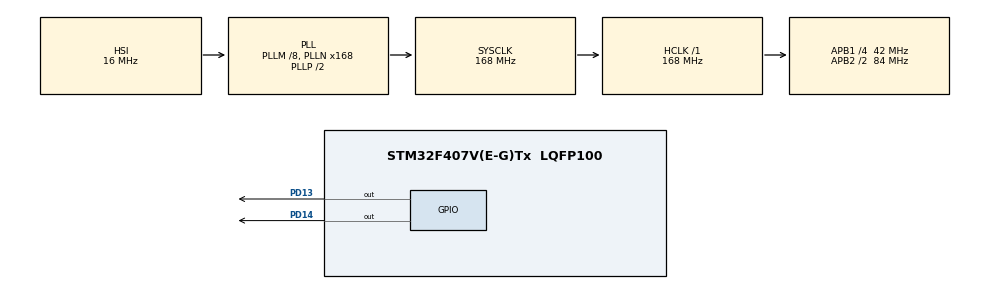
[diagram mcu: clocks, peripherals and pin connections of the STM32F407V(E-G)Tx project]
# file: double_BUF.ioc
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Mcu.Family=STM32F4
Dma.ADC1.0.Instance=DMA2_Stream0
RCC.CortexFreq_Value=168000000
ADC1.Rank-0\#ChannelRegularConversion=1
VP_ADC1_TempSens_Input.Mode=IN-TempSens
ADC1.ContinuousConvMode=ENABLE
RCC.APB1CLKDivider=RCC_HCLK_DIV4
RCC.SYSCLKSource=RCC_SYSCLKSOURCE_PLLCLK
ProjectManager.StackSize=0x400
PD13.Signal=GPIO_Output
Dma.ADC1.0.PeriphDataAlignment=DMA_PDATAALIGN_HALFWORD
ProjectManager.TargetToolchain=STM32CubeIDE
Dma.ADC1.0.Mode=DMA_CIRCULAR
RCC.HCLKFreq_Value=168000000
ADC1.Resolution=ADC_RESOLUTION_8B
Dma.ADC1.0.Priority=DMA_PRIORITY_HIGH
RCC.APB2TimFreq_Value=168000000
Dma.ADC1.0.Direction=DMA_PERIPH_TO_MEMORY
NVIC.DMA2_Stream0_IRQn=true\:0\:0\:false\:false\:true\:false\:true
Dma.ADC1.0.MemDataAlignment=DMA_MDATAALIGN_HALFWORD
RCC.AHBFreq_Value=168000000
ADC1.Channel-0\#ChannelRegularConversion=ADC_CHANNEL_TEMPSENSOR
RCC.HSE_VALUE=8000000
board=STM32F407G-DISC1
RCC.VCOOutputFreq_Value=336000000
RCC.APB2Freq_Value=84000000
Dma.ADC1.0.PeriphInc=DMA_PINC_DISABLE
ADC1.DMAContinuousRequests=ENABLE
ADC1.NbrOfConversion=1
Mcu.Name=STM32F407V(E-G)Tx
ADC1.SamplingTime-0\#ChannelRegularConversion=ADC_SAMPLETIME_28CYCLES
PD14.Signal=GPIO_Output
RCC.48MHZClocksFreq_Value=48000000
RCC.SYSCLKFreq_VALUE=168000000
Mcu.Package=LQFP100
ADC1.master=1
Dma.ADC1.0.MemInc=DMA_MINC_ENABLE
ProjectManager.HeapSize=0x200
RCC.HSI_VALUE=16000000
RCC.PLLQ=7
NVIC.PriorityGroup=NVIC_PRIORITYGROUP_0
ADC1.NbrOfConversionFlag=1
RCC.APB2CLKDivider=RCC_HCLK_DIV2
RCC.PLLM=8
RCC.PLLN=168
RCC.APB1TimFreq_Value=84000000
Dma.ADC1.0.FIFOMode=DMA_FIFOMODE_DISABLE
Dma.Request0=ADC1
RCC.APB1Freq_Value=42000000

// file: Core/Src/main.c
/* USER CODE BEGIN Header */
/**
  ******************************************************************************
  * @file           : main.c
  * @brief          : Main program body
  ******************************************************************************
  * @attention
  *
  * <h2><center>&copy; Copyright (c) 2021 STMicroelectronics.
  * All rights reserved.</center></h2>
  *
  * This software component is licensed by ST under Ultimate Liberty license
  * SLA0044, the "License"; You may not use this file except in compliance with
  * the License. You may obtain a copy of the License at:
  *                             www.st.com/SLA0044
  *
  ******************************************************************************
  */
/* USER CODE END Header */
#include "main.h"

ADC_HandleTypeDef hadc1;
DMA_HandleTypeDef hdma_adc1;

/* USER CODE BEGIN PV */
//double buffering variables
int buflen=240;
uint16_t bufDMA[480];
uint16_t buf1[240];
uint16_t buf2[240];

uint8_t DMA_status=0; //0==empty 1==half 2==full

/* USER CODE END PV */

void SystemClock_Config(void);
static void MX_GPIO_Init(void);
static void MX_DMA_Init(void);
static void MX_ADC1_Init(void);

int main(void)
{

  /* MCU Configuration--------------------------------------------------------*/

  /* Reset of all peripherals, Initializes the Flash interface and the Systick. */
  HAL_Init();

  /* Configure the system clock */
  SystemClock_Config();

  /* Initialize all configured peripherals */
  MX_GPIO_Init();
  MX_DMA_Init();
  MX_ADC1_Init();
  /* USER CODE BEGIN 2 */
  HAL_ADC_Start_DMA(&hadc1, &bufDMA, 2*buflen);

  /* USER CODE END 2 */

  /* Infinite loop */
  while (1)
  {

    /* USER CODE BEGIN 3 */

      // Start ADC Conversion
      // Pass (The ADC Instance, Result Buffer Address, Buffer Length)

  }
  /* USER CODE END 3 */
}

void SystemClock_Config(void)
{
  RCC_OscInitTypeDef RCC_OscInitStruct = {0};
  RCC_ClkInitTypeDef RCC_ClkInitStruct = {0};

  /** Configure the main internal regulator output voltage
  */
  __HAL_RCC_PWR_CLK_ENABLE();
  __HAL_PWR_VOLTAGESCALING_CONFIG(PWR_REGULATOR_VOLTAGE_SCALE1);
  /** Initializes the RCC Oscillators according to the specified parameters
  * in the RCC_OscInitTypeDef structure.
  */
  RCC_OscInitStruct.OscillatorType = RCC_OSCILLATORTYPE_HSI;
  RCC_OscInitStruct.HSIState = RCC_HSI_ON;
  RCC_OscInitStruct.HSICalibrationValue = RCC_HSICALIBRATION_DEFAULT;
  RCC_OscInitStruct.PLL.PLLState = RCC_PLL_ON;
  RCC_OscInitStruct.PLL.PLLSource = RCC_PLLSOURCE_HSI;
  RCC_OscInitStruct.PLL.PLLM = 8;
  RCC_OscInitStruct.PLL.PLLN = 168;
  RCC_OscInitStruct.PLL.PLLP = RCC_PLLP_DIV2;
  RCC_OscInitStruct.PLL.PLLQ = 7;
  if (HAL_RCC_OscConfig(&RCC_OscInitStruct) != HAL_OK)
  {
    Error_Handler();
  }
  /** Initializes the CPU, AHB and APB buses clocks
  */
  RCC_ClkInitStruct.ClockType = RCC_CLOCKTYPE_HCLK|RCC_CLOCKTYPE_SYSCLK
                              |RCC_CLOCKTYPE_PCLK1|RCC_CLOCKTYPE_PCLK2;
  RCC_ClkInitStruct.SYSCLKSource = RCC_SYSCLKSOURCE_PLLCLK;
  RCC_ClkInitStruct.AHBCLKDivider = RCC_SYSCLK_DIV1;
  RCC_ClkInitStruct.APB1CLKDivider = RCC_HCLK_DIV4;
  RCC_ClkInitStruct.APB2CLKDivider = RCC_HCLK_DIV2;

  if (HAL_RCC_ClockConfig(&RCC_ClkInitStruct, FLASH_LATENCY_5) != HAL_OK)
  {
    Error_Handler();
  }
}

static void MX_ADC1_Init(void)
{

  ADC_ChannelConfTypeDef sConfig = {0};

  /** Configure the global features of the ADC (Clock, Resolution, Data Alignment and number of conversion)
  */
  hadc1.Instance = ADC1;
  hadc1.Init.ClockPrescaler = ADC_CLOCK_SYNC_PCLK_DIV4;
  hadc1.Init.Resolution = ADC_RESOLUTION_8B;
  hadc1.Init.ScanConvMode = DISABLE;
  hadc1.Init.ContinuousConvMode = ENABLE;
  hadc1.Init.DiscontinuousConvMode = DISABLE;
  hadc1.Init.ExternalTrigConvEdge = ADC_EXTERNALTRIGCONVEDGE_NONE;
  hadc1.Init.ExternalTrigConv = ADC_SOFTWARE_START;
  hadc1.Init.DataAlign = ADC_DATAALIGN_RIGHT;
  hadc1.Init.NbrOfConversion = 1;
  hadc1.Init.DMAContinuousRequests = ENABLE;
  hadc1.Init.EOCSelection = ADC_EOC_SINGLE_CONV;
  if (HAL_ADC_Init(&hadc1) != HAL_OK)
  {
    Error_Handler();
  }
  /** Configure for the selected ADC regular channel its corresponding rank in the sequencer and its sample time.
  */
  sConfig.Channel = ADC_CHANNEL_TEMPSENSOR;
  sConfig.Rank = 1;
  sConfig.SamplingTime = ADC_SAMPLETIME_28CYCLES;
  if (HAL_ADC_ConfigChannel(&hadc1, &sConfig) != HAL_OK)
  {
    Error_Handler();
  }

}

static void MX_DMA_Init(void)
{

  /* DMA controller clock enable */
  __HAL_RCC_DMA2_CLK_ENABLE();

  /* DMA interrupt init */
  /* DMA2_Stream0_IRQn interrupt configuration */
  HAL_NVIC_SetPriority(DMA2_Stream0_IRQn, 0, 0);
  HAL_NVIC_EnableIRQ(DMA2_Stream0_IRQn);

}

static void MX_GPIO_Init(void)
{
  GPIO_InitTypeDef GPIO_InitStruct = {0};

  /* GPIO Ports Clock Enable */
  __HAL_RCC_GPIOD_CLK_ENABLE();

  /*Configure GPIO pin Output Level */
  HAL_GPIO_WritePin(GPIOD, GPIO_PIN_13|GPIO_PIN_14, GPIO_PIN_RESET);

  /*Configure GPIO pins : PD13 PD14 */
  GPIO_InitStruct.Pin = GPIO_PIN_13|GPIO_PIN_14;
  GPIO_InitStruct.Mode = GPIO_MODE_OUTPUT_PP;
  GPIO_InitStruct.Pull = GPIO_NOPULL;
  GPIO_InitStruct.Speed = GPIO_SPEED_FREQ_LOW;
  HAL_GPIO_Init(GPIOD, &GPIO_InitStruct);

}

/* USER CODE BEGIN 4 */

void window_builder(void)
{
	uint16_t i=0;

	if(DMA_status==1) //half complete
	{

		for(i=0; i < buflen; i++) {

			buf1[i]=bufDMA[i];
		}
	}

	else if(DMA_status==2) //complete
	{

		for(i=0; i < buflen; i++) {

			buf2[i]=bufDMA[240+i];
		}
	}

}

void HAL_ADC_ConvHalfCpltCallback(ADC_HandleTypeDef *hadc)
{

	DMA_status=1; //half complete
	window_builder();
    HAL_GPIO_TogglePin(GPIOD, GPIO_PIN_13);
    HAL_Delay(1);

}

void HAL_ADC_ConvCpltCallback(ADC_HandleTypeDef *hadc)
{
	DMA_status=2; //complete
	window_builder();
    HAL_GPIO_TogglePin(GPIOD, GPIO_PIN_14);
    HAL_Delay(1);

}

/* USER CODE END 4 */

void Error_Handler(void)
{
  __disable_irq();
  while (1)
  {
  }
}

/************************ (C) COPYRIGHT STMicroelectronics *****END OF FILE****/
